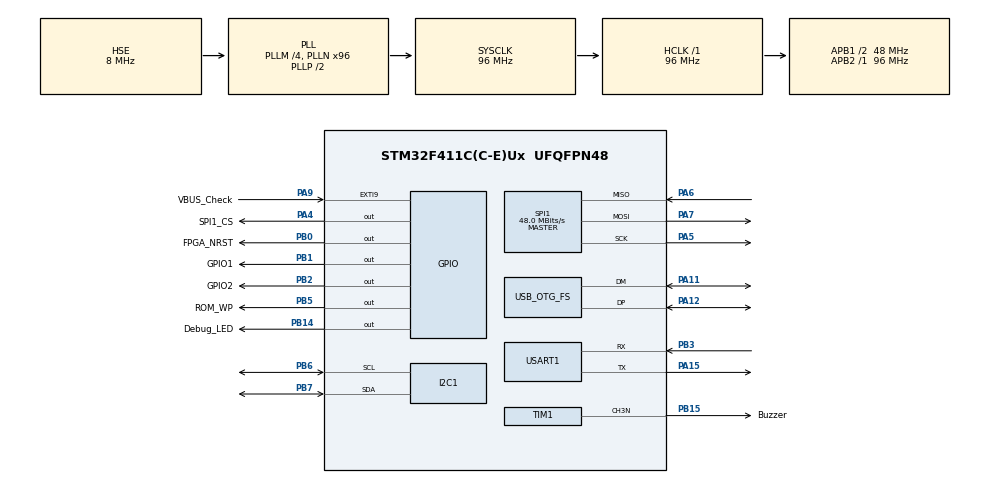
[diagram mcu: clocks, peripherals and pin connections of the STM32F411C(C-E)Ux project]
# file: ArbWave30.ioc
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Mcu.Family=STM32F4
Mcu.Name=STM32F411C(C-E)Ux
Mcu.Package=UFQFPN48
NVIC.PriorityGroup=NVIC_PRIORITYGROUP_4
NVIC.TIM1_TRG_COM_TIM11_IRQn=true\:15\:0\:false\:false\:true\:false\:true\:true
NVIC.TimeBase=TIM1_TRG_COM_TIM11_IRQn
NVIC.TimeBaseIP=TIM11
PA11.Mode=Device_Only
PA11.Signal=USB_OTG_FS_DM
PA12.Mode=Device_Only
PA12.Signal=USB_OTG_FS_DP
PA13.Mode=Serial_Wire
PA13.Signal=SYS_JTMS-SWDIO
PA14.Mode=Serial_Wire
PA14.Signal=SYS_JTCK-SWCLK
PA15.Mode=Asynchronous
PA15.Signal=USART1_TX
PA4.GPIO_Label=SPI1_CS
PA4.GPIO_Speed=GPIO_SPEED_FREQ_VERY_HIGH
PA4.PinState=GPIO_PIN_SET
PA4.Signal=GPIO_Output
PA5.Mode=Full_Duplex_Master
PA5.Signal=SPI1_SCK
PA6.Mode=Full_Duplex_Master
PA6.Signal=SPI1_MISO
PA7.Mode=Full_Duplex_Master
PA7.Signal=SPI1_MOSI
PA9.GPIO_Label=VBUS_Check
PA9.Signal=GPXTI9
PB0.GPIO_Label=FPGA_NRST
PB0.GPIO_Speed=GPIO_SPEED_FREQ_HIGH
PB0.PinState=GPIO_PIN_SET
PB0.Signal=GPIO_Output
PB1.GPIO_Label=GPIO1
PB1.GPIO_Speed=GPIO_SPEED_FREQ_VERY_HIGH
PB1.Signal=GPIO_Output
PB14.GPIO_Label=Debug_LED
PB14.Signal=GPIO_Output
PB15.GPIO_Label=Buzzer
PB15.Mode=PWM Generation3 CH3N
PB15.Signal=TIM1_CH3N
PB2.GPIO_Label=GPIO2
PB2.GPIO_Speed=GPIO_SPEED_FREQ_VERY_HIGH
PB2.PinState=GPIO_PIN_RESET
PB2.Signal=GPIO_Output
PB3.Mode=Asynchronous
PB3.Signal=USART1_RX
PB5.GPIO_Label=ROM_WP
PB5.Signal=GPIO_Output
PB6.Mode=I2C
PB6.Signal=I2C1_SCL
PB7.Mode=I2C
PB7.Signal=I2C1_SDA
PC14-OSC32_IN.Mode=LSE-External-Oscillator
PC14-OSC32_IN.Signal=RCC_OSC32_IN
PC15-OSC32_OUT.Mode=LSE-External-Oscillator
PC15-OSC32_OUT.Signal=RCC_OSC32_OUT
PH0\ -\ OSC_IN.Mode=HSE-External-Oscillator
PH0\ -\ OSC_IN.Signal=RCC_OSC_IN
PH1\ -\ OSC_OUT.Mode=HSE-External-Oscillator
PH1\ -\ OSC_OUT.Signal=RCC_OSC_OUT
ProjectManager.HeapSize=0x200
ProjectManager.StackSize=0x400
ProjectManager.TargetToolchain=MDK-ARM V5.32
RCC.48MHZClocksFreq_Value=48000000
RCC.AHBFreq_Value=96000000
RCC.APB1CLKDivider=RCC_HCLK_DIV2
RCC.APB1Freq_Value=48000000
RCC.APB1TimFreq_Value=96000000
RCC.APB2Freq_Value=96000000
RCC.APB2TimFreq_Value=96000000
RCC.CortexFreq_Value=96000000
RCC.HCLKFreq_Value=96000000
RCC.HSE_VALUE=8000000
RCC.HSI_VALUE=16000000
RCC.PLLM=4
RCC.PLLN=96
RCC.RCC_RTC_Clock_Source=RCC_RTCCLKSOURCE_LSE
RCC.RCC_RTC_Clock_SourceVirtual=RCC_RTCCLKSOURCE_LSE
RCC.RCC_RTC_Clock_Source_FROM_HSE=RCC_RTCCLKSOURCE_HSE_DIV31
RCC.SYSCLKFreq_VALUE=96000000
RCC.SYSCLKSource=RCC_SYSCLKSOURCE_PLLCLK
RCC.VCOOutputFreq_Value=192000000
SPI1.BaudRatePrescaler=SPI_BAUDRATEPRESCALER_2
SPI1.CalculateBaudRate=48.0 MBits/s
SPI1.Direction=SPI_DIRECTION_2LINES
SPI1.Mode=SPI_MODE_MASTER
SPI1.VirtualType=VM_MASTER
TIM1.Channel-PWM\ Generation3\ CH3N=TIM_CHANNEL_3
USART1.VirtualMode=VM_ASYNC
USB_OTG_FS.VirtualMode=Device_Only
VP_RTC_VS_RTC_Activate.Mode=RTC_Enabled
VP_RTC_VS_RTC_Calendar.Mode=RTC_Calendar
VP_SYS_VS_tim11.Mode=TIM11
VP_TIM1_VS_ClockSourceINT.Mode=Internal
board=custom

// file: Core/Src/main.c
/* USER CODE BEGIN Header */
/**
  ******************************************************************************
  * @file           : main.c
  * @brief          : Main program body
  ******************************************************************************
  * @attention
  *
  * Copyright (c) 2026 STMicroelectronics.
  * All rights reserved.
  *
  * This software is licensed under terms that can be found in the LICENSE file
  * in the root directory of this software component.
  * If no LICENSE file comes with this software, it is provided AS-IS.
  *
  ******************************************************************************
  */
/* USER CODE END Header */
#include "main.h"
#include "i2c.h"
#include "rtc.h"
#include "spi.h"
#include "tim.h"
#include "usart.h"
#include "usb_otg.h"
#include "gpio.h"

void SystemClock_Config(void);

int main(void)
{

  /* MCU Configuration--------------------------------------------------------*/

  /* Reset of all peripherals, Initializes the Flash interface and the Systick. */
  HAL_Init();

  /* Configure the system clock */
  SystemClock_Config();

  /* Initialize all configured peripherals */
  MX_GPIO_Init();
  MX_I2C1_Init();
  MX_SPI1_Init();
  MX_USART1_UART_Init();
  MX_RTC_Init();
  MX_TIM1_Init();
  MX_USB_OTG_FS_PCD_Init();

  /* Infinite loop */
  /* USER CODE BEGIN WHILE */
  while (1)
  {
    HAL_GPIO_TogglePin(Debug_LED_GPIO_Port, Debug_LED_Pin);
    HAL_Delay(500 - 1);
    /* USER CODE END WHILE */

  }
}

void SystemClock_Config(void)
{
  RCC_OscInitTypeDef RCC_OscInitStruct = {0};
  RCC_ClkInitTypeDef RCC_ClkInitStruct = {0};

  /** Configure the main internal regulator output voltage
  */
  __HAL_RCC_PWR_CLK_ENABLE();
  __HAL_PWR_VOLTAGESCALING_CONFIG(PWR_REGULATOR_VOLTAGE_SCALE1);

  /** Initializes the RCC Oscillators according to the specified parameters
  * in the RCC_OscInitTypeDef structure.
  */
  RCC_OscInitStruct.OscillatorType = RCC_OSCILLATORTYPE_HSE|RCC_OSCILLATORTYPE_LSE;
  RCC_OscInitStruct.HSEState = RCC_HSE_ON;
  RCC_OscInitStruct.LSEState = RCC_LSE_ON;
  RCC_OscInitStruct.PLL.PLLState = RCC_PLL_ON;
  RCC_OscInitStruct.PLL.PLLSource = RCC_PLLSOURCE_HSE;
  RCC_OscInitStruct.PLL.PLLM = 4;
  RCC_OscInitStruct.PLL.PLLN = 96;
  RCC_OscInitStruct.PLL.PLLP = RCC_PLLP_DIV2;
  RCC_OscInitStruct.PLL.PLLQ = 4;
  if (HAL_RCC_OscConfig(&RCC_OscInitStruct) != HAL_OK)
  {
    Error_Handler();
  }

  /** Initializes the CPU, AHB and APB buses clocks
  */
  RCC_ClkInitStruct.ClockType = RCC_CLOCKTYPE_HCLK|RCC_CLOCKTYPE_SYSCLK
                              |RCC_CLOCKTYPE_PCLK1|RCC_CLOCKTYPE_PCLK2;
  RCC_ClkInitStruct.SYSCLKSource = RCC_SYSCLKSOURCE_PLLCLK;
  RCC_ClkInitStruct.AHBCLKDivider = RCC_SYSCLK_DIV1;
  RCC_ClkInitStruct.APB1CLKDivider = RCC_HCLK_DIV2;
  RCC_ClkInitStruct.APB2CLKDivider = RCC_HCLK_DIV1;

  if (HAL_RCC_ClockConfig(&RCC_ClkInitStruct, FLASH_LATENCY_3) != HAL_OK)
  {
    Error_Handler();
  }
}

void HAL_TIM_PeriodElapsedCallback(TIM_HandleTypeDef *htim)
{
  if (htim->Instance == TIM11) {
    HAL_IncTick();
  }
}

void Error_Handler(void)
{
  __disable_irq();
  while (1)
  {
  }
}
